# PIC32MK0256GPH048 device description
Architecture: MIPS; Family: PIC32MK; Series: PIC32MK
Registers are 32-bit, read-write, no defined reset value unless marked. A register's access mark holds for its fields unless they carry their own. Offsets are from the block's base; [hi:lo] are bit positions; {n}, {i} and the like mark numbered series.

## DMAC
Instances: DMAC 0x1f811000 in periph_pb1_fast
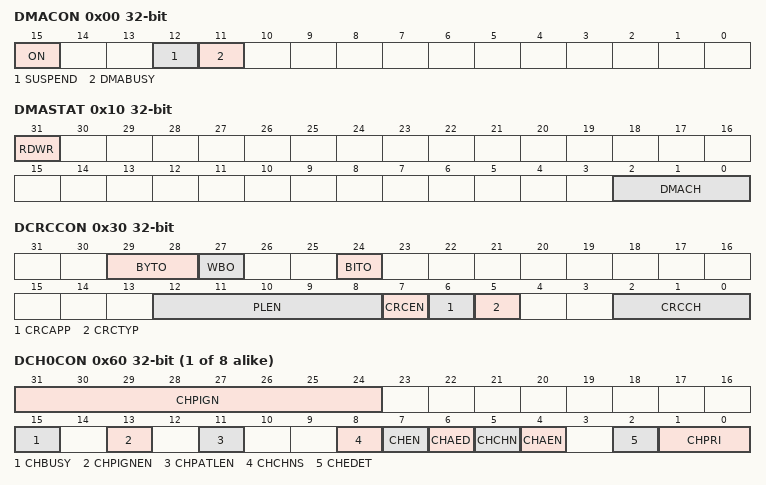
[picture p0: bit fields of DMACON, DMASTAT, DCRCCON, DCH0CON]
0x00 DMACON — DMA Controller Control Register
  [15] ON — DMA On bit
    1=DMA module is enabled; 0=DMA module is disabled
  [12] SUSPEND — DMA Suspend bit
    1=DMA transfers are suspended to allow CPU uninterrupted access to data bus; 0=DMA operates normally
  [11] DMABUSY — DMA Module Busy bit
    1=DMA module is active and is transferring data; 0=DMA module is disabled and not actively transferring data
0x10 DMASTAT ro — DMA Status Register
  [31] RDWR — Read/Write Status bit
    1=Last DMA bus access when an error was detected was a read; 0=Last DMA bus access when an error was detected was a write
  [2:0] DMACH
0x20 DMAADDR ro — DMA Address Register
0x30 DCRCCON — DMA CRC Control Register
  [29:28] BYTO — CRC Byte Order Selection bits
    3=Endian byte swap on half-word boundaries; 2=Swap half-words on word boundaries; 1=Endian byte swap on word boundaries; 0=No swapping
  [27] WBO — CRC Write Byte Order Selection bit
    1=Source data is written to the destination re-ordered as defined by BYTO; 0=Source data is written to the destination unaltered
  [24] BITO — CRC Bit Order Selection bit
    1=(When CRCTYP (ie; 0=(When CRCTYP (i.e
  [12:8] PLEN — Polynomial Length bits
    When CRCTYP (DCRCCON)=1 (CRC module is in IP Header mode)These bits are unused; When CRCTYP (DCRCCON)=0 (CRC module is in LFSR mode) Denotes the length of the polynomial minus 1
  [7] CRCEN — CRC Enable bit
    1=CRC module is enabled and channel transfers are routed through the CRC module; 0=CRC module is disabled and channel transfers proceed normally
  [6] CRCAPP — CRC Append Mode bit
    1=The DMA transfers data from the source into the CRC but NOT to the destination. When a block transfer completes the DMA writes the calculated CRC value to the location given by CHxDSA; 0=The DMA transfers data from the source through the CRC obeying WBO as it writes the data to the destination
  [5] CRCTYP — CRC Type Selection bit
    1=The CRC module will calculate an IP header checksum; 0=The CRC module will calculate a LFSR CRC
  [2:0] CRCCH — CRC Channel Select bits
    {v}=CRC is assigned to Channel {v} (v=0..7)
0x40 DCRCDATA — DMA CRC Data Register
  [31:0] DCRCDATA — CRC Data Register bits
    When CRCTYP (DCRCCON)=1 (CRC module is in IP Header mode) Only the lower 16 bits contain IP header checksum information. The upper 16 bits are always 0. Data written to this register is converted and read back in 1s complement form (i.e.; When CRCTYP (DCRCCON)=0 (CRC module is in LFSR mode) Bits greater than PLEN will return 0 on any read
0x50 DCRCXOR — DMA CRCXOR Enable Register
  [31:0] DCRCXOR — CRC XOR Register bits
    1=(When CRCTYP is 0) Enable the XOR input to the Shift register / (When CRCTYP is 1) This register is unused; 0=(When CRCTYP is 0) Disable the XOR input to the Shift register; data is shifted in directly from the previous stage in the register/ When CRCTYP is 1) This register is unused
{0x60+0xC0*i} DCH{i}CON (i=0..7) — DMA Channel x Control Register
  [31:24] CHPIGN
  [15] CHBUSY — Channel Busy bit
    1=Channel is active or has been enabled; 0=Channel is inactive or has been disabled
  [13] CHPIGNEN — Enable Pattern Ignore Byte bit
    1=Treat any byte that matches the CHPIGN bits as a dont care when pattern matching is enabled; 0=Disable this feature
  [11] CHPATLEN — Pattern Length bit
    1=2 byte length; 0=1 byte length
  [8] CHCHNS — Chain Channel Selection bit
    1=Chain to channel lower in natural priority (CH1 will be enabled by CH2 transfer complete); 0=Chain to channel higher in natural priority (CH1 will be enabled by CH0 transfer complete)
  [7] CHEN — Channel Enable bit
    1=Channel is enabled; 0=Channel is disabled
  [6] CHAED — Channel Allow Events If Disabled bit
    1=Channel start/abort events will be registered; 0=Channel start/abort events will be ignored if the channel is disabled
  [5] CHCHN — Channel Chain Enable bit
    1=Allow channel to be chained; 0=Do not allow channel to be chained
  [4] CHAEN — Channel Automatic Enable bit
    1=Channel is continuously enabled; 0=Channel is disabled on block transfer complete
  [2] CHEDET — Channel Event Detected bit
    1=An event has been detected; 0=No events have been detected
  [1:0] CHPRI — Channel Priority bits
    3=Channel has priority 3 (highest); 2=Channel has priority 2; 1=Channel has priority 1; 0=Channel has priority 0
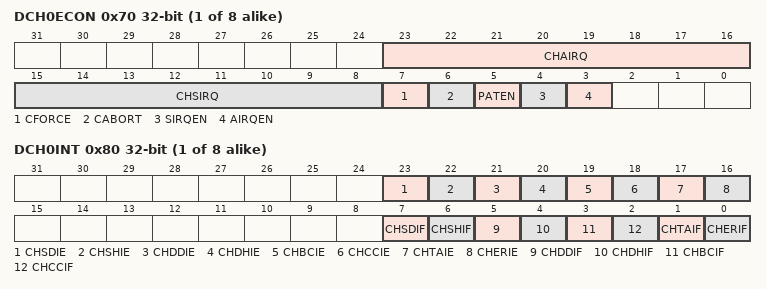
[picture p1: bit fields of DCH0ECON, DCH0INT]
{0x70+0xC0*i} DCH{i}ECON (i=0..7) — DMA Channel x Event Control Register
  [23:16] CHAIRQ — Channel Transfer Abort IRQ bits
    255=Interrupt 255 will abort any transfers in progress and set CHAIF flag; 1=Interrupt 1 will abort any transfers in progress and set CHAIF flag; 0=Interrupt 0 will abort any transfers in progress and set CHAIF flag
  [15:8] CHSIRQ — Channel Transfer Start IRQ bits
    255=Interrupt 255 will initiate a DMA transfer; 1=Interrupt 1 will initiate a DMA transfer; 0=Interrupt 0 will initiate a DMA transfer
  [7] CFORCE — DMA Forced Transfer bit
    1=A DMA transfer is forced to begin when this bit is written to a 1; 0=This bit always reads 0
  [6] CABORT — DMA Abort Transfer bit
    1=A DMA transfer is aborted when this bit is written to a 1; 0=This bit always reads 0
  [5] PATEN — Channel Pattern Match Abort Enable bit
    1=Abort transfer and clear CHEN on pattern match; 0=Pattern match is disabled
  [4] SIRQEN — Channel Start IRQ Enable bit
    1=Start channel cell transfer if an interrupt matching CHSIRQ occurs; 0=Interrupt number CHSIRQ is ignored and does not start a transfer
  [3] AIRQEN — Channel Abort IRQ Enable bit
    1=Channel transfer is aborted if an interrupt matching CHAIRQ occurs; 0=Interrupt number CHAIRQ is ignored and does not terminate a transfer
{0x80+0xC0*i} DCH{i}INT (i=0..7) — DMA Channel x Interrupt Control Register
  [23] CHSDIE — Channel Source Done Interrupt Enable bit
    1=Interrupt is enabled; 0=Interrupt is disabled
  [22] CHSHIE — Channel Source Half Empty Interrupt Enable bit
    1=Interrupt is enabled; 0=Interrupt is disabled
  [21] CHDDIE — Channel Destination Done Interrupt Enable bit
    1=Interrupt is enabled; 0=Interrupt is disabled
  [20] CHDHIE — Channel Destination Half Full Interrupt Enable bit
    1=Interrupt is enabled; 0=Interrupt is disabled
  [19] CHBCIE — Channel Block Transfer Complete Interrupt Enable bit
    1=Interrupt is enabled; 0=Interrupt is disabled
  [18] CHCCIE — Channel Cell Transfer Complete Interrupt Enable bit
    1=Interrupt is enabled; 0=Interrupt is disabled
  [17] CHTAIE — Channel Transfer Abort Interrupt Enable bit
    1=Interrupt is enabled; 0=Interrupt is disabled
  [16] CHERIE — Channel Address Error Interrupt Enable bit
    1=Interrupt is enabled; 0=Interrupt is disabled
  [7] CHSDIF — Channel Source Done Interrupt Flag bit
    1=Channel Source Pointer has reached end of source (CHSPTR = CHSSIZ); 0=No interrupt is pending
  [6] CHSHIF — Channel Source Half Empty Interrupt Flag bit
    1=Channel Source Pointer has reached midpoint of source (CHSPTR = CHSSIZ/2); 0=No interrupt is pending
  [5] CHDDIF — Channel Destination Done Interrupt Flag bit
    1=Channel Destination Pointer has reached end of destination (CHDPTR = CHDSIZ); 0=No interrupt is pending
  [4] CHDHIF — Channel Destination Half Full Interrupt Flag bit
    1=Channel Destination Pointer has reached midpoint of destination (CHDPTR = CHDSIZ/2); 0=No interrupt is pending
  [3] CHBCIF — Channel Block Transfer Complete Interrupt Flag bit
    1=A block transfer has been completed (the larger of CHSSIZ/CHDSIZ bytes has been transferred); 0=No interrupt is pending
  [2] CHCCIF — Channel Cell Transfer Complete Interrupt Flag bit
    1=A cell transfer has been completed (CHCSIZ bytes have been transferred); 0=No interrupt is pending
  [1] CHTAIF — Channel Transfer Abort Interrupt Flag bit
    1=An interrupt matching CHAIRQ has been detected and the DMA transfer has been aborted; 0=No interrupt is pending
  [0] CHERIF — Channel Address Error Interrupt Flag bit
    1=A channel address error has been detected Either the source or the destination address is invalid; 0=No interrupt is pending
{0x90+0xC0*i} DCH{i}SSA (i=0..7) — DMA Channel x Source Start Address Register
  [31:0] CHSSA
{0xA0+0xC0*i} DCH{i}DSA (i=0..7) — DMA Channel x Destination Start Address Register
  [31:0] CHDSA
{0xB0+0xC0*i} DCH{i}SSIZ (i=0..7) — DMA Channel x Source Size Register
  [15:0] CHSSIZ — Channel Source Size bits
    2=2 byte source size; 1=1 byte source size; 0=65536 byte source size
{0xC0+0xC0*i} DCH{i}DSIZ (i=0..7) — DMA Channel x Destination Size Register
  [15:0] CHDSIZ — Channel Destination Size bits
    2=2 byte destination size; 1=1 byte destination size; 0=65536 byte destination size
{0xD0+0xC0*i} DCH{i}SPTR (i=0..7) — DMA Channel x Source Pointer Register
  [15:0] CHSPTR — Channel Source Pointer bits
    0xffff=Points to byte 65535 of the source; 1=Points to byte 1 of the source; 0=Points to byte 0 of the source
{0xE0+0xC0*i} DCH{i}DPTR (i=0..7) — DMA Channel x Destination Pointer Register
  [15:0] CHDPTR — Channel Destination Pointer bits
    0xffff=Points to byte 65535 of the destination; 1=Points to byte 1 of the destination; 0=Points to byte 0 of the destination
{0xF0+0xC0*i} DCH{i}CSIZ (i=0..7) — DMA Channel x Cell-Size Register
  [15:0] CHCSIZ — Channel Cell-Size bits
    0xffff=65535 bytes transferred on an event; 2=2 bytes transferred on an event; 1=1 byte transferred on an event; 0=65536 bytes transferred on an event
{0x100+0xC0*i} DCH{i}CPTR (i=0..7) — DMA Channel x Cell Pointer Register
  [15:0] CHCPTR — Channel Cell Progress Pointer bits
    0xffff=65535 bytes have been transferred since the last event; 1=1 byte has been transferred since the last event; 0=0 bytes have been transferred since the last event
{0x110+0xC0*i} DCH{i}DAT (i=0..7) — DMA Channel x Pattern Data Register
  [15:0] CHPDAT

## Notices in the file
Copyright (c) 2019 Microchip Technology Inc.
SPDX-License-Identifier: Apache-2.0
Licensed under the Apache License, Version 2.0 (the "License");
you may not use this file except in compliance with the License.
You may obtain a copy of the License at
http://www.apache.org/licenses/LICENSE-2.0
Unless required by applicable law or agreed to in writing, software
distributed under the License is distributed on an "AS IS" BASIS,
WITHOUT WARRANTIES OR CONDITIONS OF ANY KIND, either express or implied.
See the License for the specific language governing permissions and
limitations under the License.
